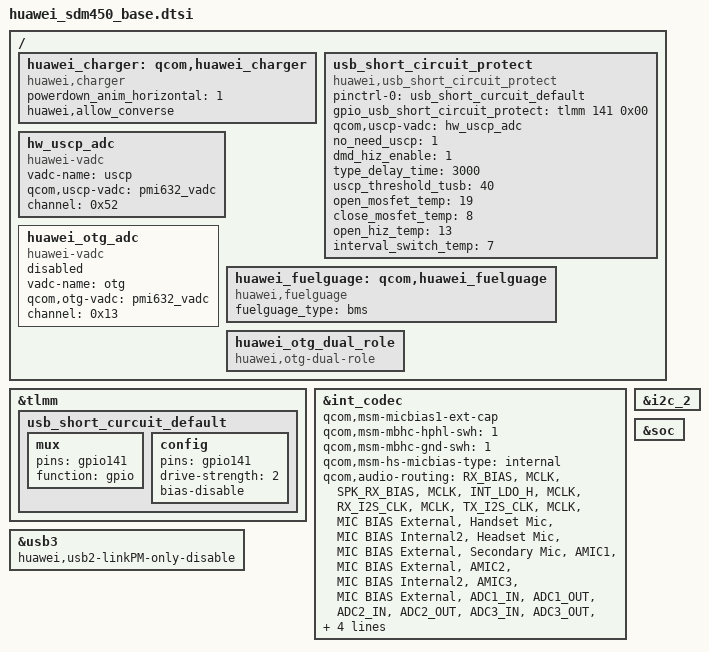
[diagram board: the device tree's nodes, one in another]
#include "sdm450.dtsi"
#include "sdm450-pmi632.dtsi"
#include "sdm450-qrd-sku4.dtsi"
 /{
     huawei_charger: qcom,huawei_charger{
         compatible = "huawei,charger";
         status = "okay";
         powerdown_anim_horizontal = "1";
         huawei,allow_converse;

     };
 };

&tlmm {
    usb_short_curcuit_default: usb_short_curcuit_default {
	mux {
		pins = "gpio141";
		function = "gpio";
	};
	config {
		pins = "gpio141";
		drive-strength = <2>;
		bias-disable;
	};
    };
};
/{
    usb_short_circuit_protect: usb_short_circuit_protect{
	compatible = "huawei,usb_short_circuit_protect";
	pinctrl-names = "default";
	pinctrl-0 = <&usb_short_curcuit_default>;
	gpio_usb_short_circuit_protect = <&tlmm 141 0x00>;
	qcom,uscp-vadc = <&hw_uscp_adc>;
	no_need_uscp = <1>;
	dmd_hiz_enable = <1>;
	type_delay_time = <3000>;
	uscp_threshold_tusb = <40>;
	open_mosfet_temp = <19>;
	close_mosfet_temp = <8>;
	open_hiz_temp = <13>;
	interval_switch_temp = <7>;
	status = "ok";
    };
};
/{
    hw_uscp_adc: hw_uscp_adc {
	compatible="huawei-vadc";
	vadc-name="uscp";
	qcom,uscp-vadc=<&pmi632_vadc>;
	channel = <0x52>;
	status="okay";
    };
    huawei_otg_adc: huawei_otg_adc {
    	compatible="huawei-vadc";
    	vadc-name="otg";
    	qcom,otg-vadc=<&pmi632_vadc>;
    	channel = <0x13>;
    	status="disabled";
    };
};

 /{
     huawei_fuelguage: qcom,huawei_fuelguage{
         compatible = "huawei,fuelguage";
         fuelguage_type = "bms";
         status = "okay";
     };
 };

 / {
	huawei_otg_dual_role:huawei_otg_dual_role{
		compatible = "huawei,otg-dual-role";
		status = "okay";
	};
};

&int_codec {
    status = "okay";
    qcom,msm-micbias1-ext-cap;
    qcom,msm-mbhc-hphl-swh = <1>;
    qcom,msm-mbhc-gnd-swh = <1>;
    qcom,msm-hs-micbias-type = "internal";
    /delete-property/ asoc-wsa-codec-names;
    qcom,audio-routing =
        "RX_BIAS", "MCLK",
        "SPK_RX_BIAS", "MCLK",
        "INT_LDO_H", "MCLK",
        "RX_I2S_CLK", "MCLK",
        "TX_I2S_CLK", "MCLK",
        "MIC BIAS External", "Handset Mic",
        "MIC BIAS Internal2", "Headset Mic",
        "MIC BIAS External", "Secondary Mic",
        "AMIC1", "MIC BIAS External",
        "AMIC2", "MIC BIAS Internal2",
        "AMIC3", "MIC BIAS External",
        "ADC1_IN", "ADC1_OUT",
        "ADC2_IN", "ADC2_OUT",
        "ADC3_IN", "ADC3_OUT",
        "PDM_IN_RX1", "PDM_OUT_RX1",
        "PDM_IN_RX2", "PDM_OUT_RX2",
        "PDM_IN_RX3", "PDM_OUT_RX3",
        "WSA_SPK OUT", "VDD_WSA_SWITCH",
        "SpkrMono WSA_IN", "WSA_SPK OUT";
};

&i2c_2 {
    /delete-node/ wsa881x-i2c-codec@f;
    /delete-node/ wsa881x-i2c-codec@45;
};

&soc {
    /delete-node/ wsa881x_analog_vi_pctrl;
    /delete-node/ wsa881x_analog_clk_pctrl;
    /delete-node/ wsa881x_analog_reset_pctrl;
};

&usb3 {
    huawei,usb2-linkPM-only-disable;
};

